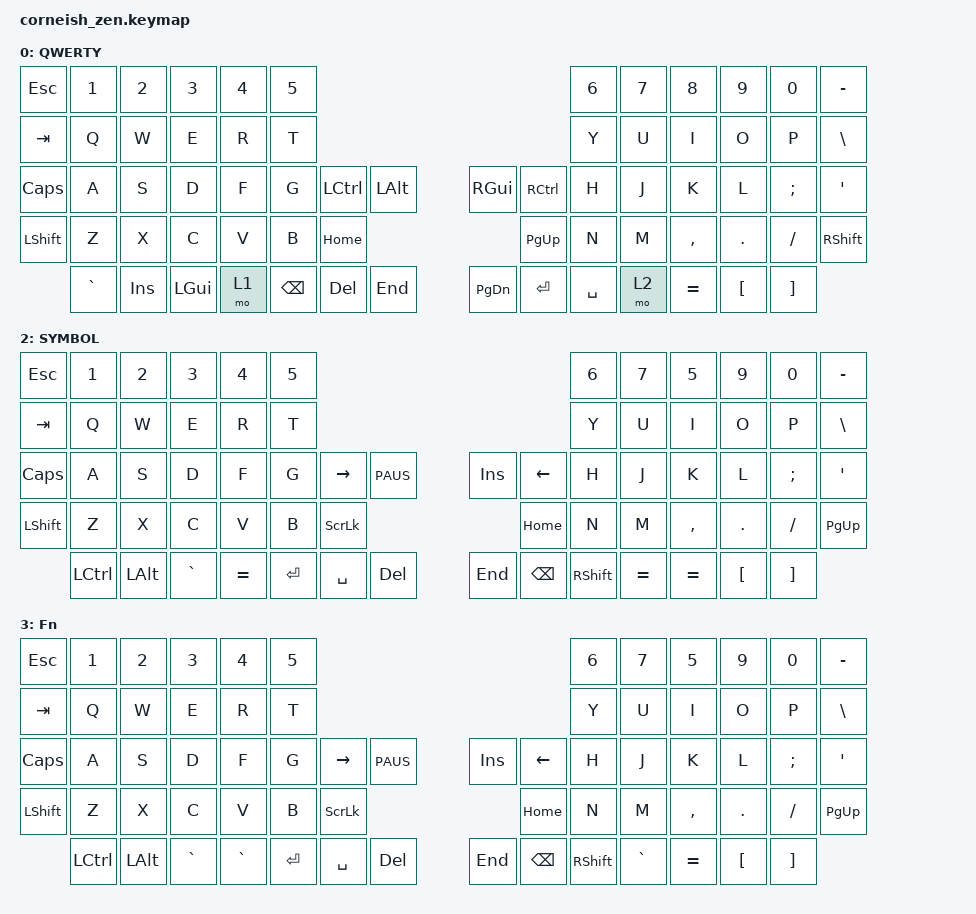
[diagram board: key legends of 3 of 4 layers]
/*
 * Copyright (c) 2020 The ZMK Contributors
 *
 * SPDX-License-Identifier: MIT
 */

#include <behaviors.dtsi>
#include <dt-bindings/zmk/bt.h>
#include <dt-bindings/zmk/ext_power.h>
#include <dt-bindings/zmk/keys.h>
#include <dt-bindings/zmk/outputs.h>
#include <dt-bindings/zmk/rgb.h>

/ {
    chosen {
        zmk,matrix_transform = &default_transform;

        // zmk,matrix_transform = &five_column_transform;
    };
};

/ {
    behaviors {
        td0: td0 {
            compatible = "zmk,behavior-tap-dance";
            label = "TD0";
            #binding-cells = <0>;
            bindings = <&kp LEFT_SHIFT>, <&kp CAPS>;
        };
    };

    keymap {
        compatible = "zmk,keymap";

        default_layer {
            display-name = "QWERTY";

            

            bindings = <
        &kp ESC        &kp N1    &kp N2   &kp N3    &kp N4    &kp N5                                                                              &kp N6  &kp N7        &kp N8    &kp N9    &kp N0   &kp MINUS
    &kp TAB        &kp Q     &kp W    &kp E     &kp R     &kp T                                                                               &kp Y   &kp U         &kp I     &kp O     &kp P    &kp BSLH
    &kp CLCK       &kp A     &kp S    &kp D     &kp F     &kp G            &kp LCTRL &kp LALT             &kp RIGHT_GUI &kp RCTRL             &kp H   &kp J         &kp K     &kp L     &kp SEMI &kp SQT
    &kp LSHFT      &kp Z     &kp X    &kp C     &kp V     &kp B                      &kp HOME              &kp PG_UP                          &kp N   &kp M         &kp COMMA &kp DOT   &kp FSLH &kp RSHFT 
                   &kp GRAVE  &kp INSERT &kp LGUI  &mo 1          &kp BSPC  &kp DELETE &kp END            &kp PG_DN &kp ENTER &kp SPACE                 &mo 2     &kp EQUAL &kp LBKT  &kp RBKT   
                                                         
            >;
        };

        lower_layer {
            display-name = "NUMBER";

            // Left: F-keys & BT controls | Right: Numpad centered on home row
            // Operators flank the number pad on left/right pinky columns

            bindings = <
        &trans        &kp F1           &kp F2            &kp F3           &kp F4           &kp F5                                                                                          &kp EQUAL  &kp PRCNT  &kp CARET  &kp DLLR   &kp HASH   &kp BSPC
        &kp GRAVE     &kp F6           &kp F7            &kp F8           &kp F9           &kp F10                                                                                         &kp LPAR   &kp N7     &kp N8     &kp N9     &kp RPAR   &kp DEL
        &trans        &kp F11          &kp F12           &trans           &kp LBRC         &kp RBRC         &trans    &trans                 &trans     &trans                             &kp FSLH   &kp N4     &kp N5     &kp N6     &kp ASTRK  &kp EQUAL
        &bt BT_CLR    &bt BT_SEL 0     &bt BT_SEL 1      &bt BT_SEL 2     &bt BT_SEL 3     &bt BT_SEL 4               &trans                 &trans                                        &kp MINUS  &kp N1     &kp N2     &kp N3     &kp PLUS   &kp RET
                      &kp LALT         &ext_power EP_OFF &ext_power EP_ON &trans                    &kp ENTER &kp SPACE &kp DEL              &trans     &kp BSPC   &kp SPACE                          &kp N0     &kp DOT    &kp COMMA
>;
        };

        raise_layer {
            display-name = "SYMBOL";

            

            bindings = <
        &kp ESC        &kp N1    &kp N2   &kp N3    &kp N4    &kp N5                                                                              &kp N6  &kp N7        &kp N5    &kp N9    &kp N0   &kp MINUS
    &kp TAB        &kp Q     &kp W    &kp E     &kp R     &kp T                                                                               &kp Y   &kp U         &kp I     &kp O     &kp P    &kp BSLH
    &kp CLCK       &kp A     &kp S    &kp D     &kp F     &kp G            &kp RIGHT &kp PAUS             &kp INSERT &kp LEFT                &kp H   &kp J         &kp K     &kp L     &kp SEMI &kp SQT
    &kp LSHFT      &kp Z     &kp X    &kp C     &kp V     &kp B                      &kp SLCK              &kp HOME                           &kp N   &kp M         &kp COMMA &kp DOT   &kp FSLH &kp PG_UP
                   &kp LCTRL  &kp LALT &kp GRAVE &kp EQUAL       &kp ENTER  &kp SPACE &kp DELETE            &kp END &kp BSPC &kp RSHFT                 &kp EQUAL     &kp EQUAL &kp LBKT  &kp RBKT        
                       

            >;
        };

        layer_3 {
            display-name = "Fn";
            bindings = <
 &kp ESC        &kp N1    &kp N2   &kp N3    &kp N4    &kp N5                                                                              &kp N6  &kp N7        &kp N5    &kp N9    &kp N0   &kp MINUS
    &kp TAB        &kp Q     &kp W    &kp E     &kp R     &kp T                                                                               &kp Y   &kp U         &kp I     &kp O     &kp P    &kp BSLH
    &kp CLCK       &kp A     &kp S    &kp D     &kp F     &kp G            &kp RIGHT &kp PAUS             &kp INSERT &kp LEFT                &kp H   &kp J         &kp K     &kp L     &kp SEMI &kp SQT
    &kp LSHFT      &kp Z     &kp X    &kp C     &kp V     &kp B                      &kp SLCK              &kp HOME                           &kp N   &kp M         &kp COMMA &kp DOT   &kp FSLH &kp PG_UP
                   &kp LCTRL  &kp LALT &kp GRAVE &kp GRAVE      &kp ENTER  &kp SPACE &kp DELETE            &kp END &kp BSPC &kp RSHFT                 &kp GRAVE     &kp EQUAL &kp LBKT  &kp RBKT        
            >;
        };
    };
};
